# LPC5411x register map
Vendor: nxp.com; File version: 1.2
CPU: CM4 r0p1, little endian, MPU, FPU, VTOR, vendor SysTick, 3 interrupt priority bits
Registers are 32-bit, read-write, reset 0x0 unless marked. A register's access mark holds for its fields unless they carry their own. Offsets are from the block's base; [hi:lo] are bit positions; 'fields as' and 'values as' point back to an identical list.

## DMIC — LPC5411x Windowed Watchdog Timer (WWDT)
Base 0x40090000
0x00 OSR0 — Oversample Rate register 0
  [7:0] OSR — Selects the oversample rate for the related input channel.
0x04 DIVHFCLK0 — DMIC Clock Register 0
  [3:0] PDMDIV — PDM clock divider value. 0 = divide by 1 1 = divide by 2 2 = divide by 3 3 = divide by 4 4 = divide by 6 5 = divide by 8 6 = divide by 12 7 = divide by 16 8 = divide by 24 9 = divide by 32 10 = divide by 48 11 = divide by 64 12 = divide by 96 13 = divide by 128 others = reserved.
0x08 PREAC2FSCOEF0 — Pre-Emphasis Filter Coefficient for 2 FS register
  [1:0] COMP — Pre-emphasis filer coefficient for 2 FS mode. 0 = Compensation = 0 1 = Compensation = 16 2 = Compensation = 15 3 = Compensation = 13
0x0C PREAC4FSCOEF0 — Pre-Emphasis Filter Coefficient for 4 FS register
  [1:0] COMP — Pre-emphasis filer coefficient for 4 FS mode. 0 = Compensation = 0 1 = Compensation = 16 2 = Compensation = 15 3 = Compensation = 13
0x10 GAINSHIFT0 — Decimator Gain Shift register
  [5:0] GAIN — Gain control, as a positive or negative (two's complement) number of bits to shift.
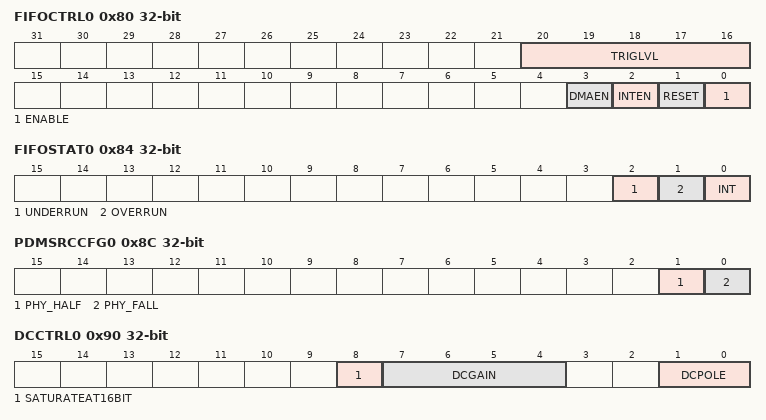
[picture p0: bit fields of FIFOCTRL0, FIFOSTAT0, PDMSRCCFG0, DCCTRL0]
0x80 FIFOCTRL0 — FIFO Control register 0
  [20:16] TRIGLVL — FIFO trigger level. Selects the data trigger level for interrupt or DMA operation. If enabled to do so, the FIFO level can wake up the device just enough to perform DMA, then return to the reduced power mode See Section 4.5.66 'Hardware Wake-up control register'. 0 = trigger when the FIFO has received one entry (is no longer empty). 1 = trigger when the FIFO has received two entries. 15 = trigger when the FIFO has received 16 entries (has become full).
  [3] DMAEN — DMA enable
    0=DISABLED (DMA requests are not enabled.); 1=ENABLED (DMA requests based on FIFO level are enabled.)
  [2] INTEN — Interrupt enable.
    0=DISABLED (FIFO level interrupts are not enabled.); 1=ENABLED (FIFO level interrupts are enabled.)
  [1] RESET — FIFO reset.
    0=NORMAL (Normal operation); 1=RESET (Reset the FIFO. This bit must be cleared before resuming operation)
  [0] ENABLE — FIFO enable.
    0=DISABLED (FIFO is not enabled. Enabling a DMIC channel with the FIFO disabled could be useful while data is being streamed to the I2S, or in order to avoid a filter settling delay when a channel is re-enabled after a period when the data was not needed.); 1=ENABLED (FIFO is enabled. The FIFO must be enabled in order for the CPU or DMA to read data from the DMIC via the FIFODATA register.)
0x84 FIFOSTAT0 — FIFO Status register 0
  [2] UNDERRUN — Underrun flag. Indicates that a FIFO underflow has occurred at some point. Writing a one to this bit clears the flag.
  [1] OVERRUN — Overrun flag. Indicates that a FIFO overflow has occurred at some point. Writing a one to this bit clears the flag. This flag does not cause an interrupt.
  [0] INT — Interrupt flag. Asserted when FIFO data reaches the level specified in the FIFOCTRL register. Writing a one to this bit clears the flag. Remark: note that the bus clock to the DMIC subsystem must be running in order for an interrupt to occur.
0x88 FIFODATA0 — FIFO Data Register 0
  [23:0] DATA — Data from the top of the input filter FIFO.
0x8C PDMSRCCFG0 — PDM Source Configuration register 0
  [1] PHY_HALF — Half rate sampling
    0=STANDARD (Standard half rate sampling. The clock to the DMIC is sent at the same rate as the decimator is providing.); 1=HALF_RATE (Use half rate sampling. The clock to the DMIC is sent at half the rate as the decimator is providing.)
  [0] PHY_FALL — Capture PDM_DATA
    0=RISING_EDGE (Capture PDM_DATA on the rising edge of PDM_CLK.); 1=FALLING_EDGE (Capture PDM_DATA on the falling edge of PDM_CLK.)
0x90 DCCTRL0 — DC Control register 0
  [8] SATURATEAT16BIT — Selects 16-bit saturation.
    0=DO_NOT_SATURATE (Results roll over if out range and do not saturate.); 1=SATURATE (If the result overflows, it saturates at 0xFFFF for positive overflow and 0x8000 for negative overflow.)
  [7:4] DCGAIN — Fine gain adjustment in the form of a number of bits to downshift.
  [1:0] DCPOLE — DC block filter
    0=FLAT_RESPONSE (Flat response, no filter.); 1=155_HZ; 2=78_HZ; 3=39_HZ
0x100 OSR1 — Oversample Rate register 1
  fields as OSR0
0x104 DIVHFCLK1 — DMIC Clock Register 1
  fields as DIVHFCLK0
0x108 PREAC2FSCOEF1 — Pre-Emphasis Filter Coefficient for 2 FS register
  fields as PREAC2FSCOEF0
0x10C PREAC4FSCOEF1 — Pre-Emphasis Filter Coefficient for 4 FS register
  fields as PREAC4FSCOEF0
0x110 GAINSHIFT1 — Decimator Gain Shift register
  fields as GAINSHIFT0
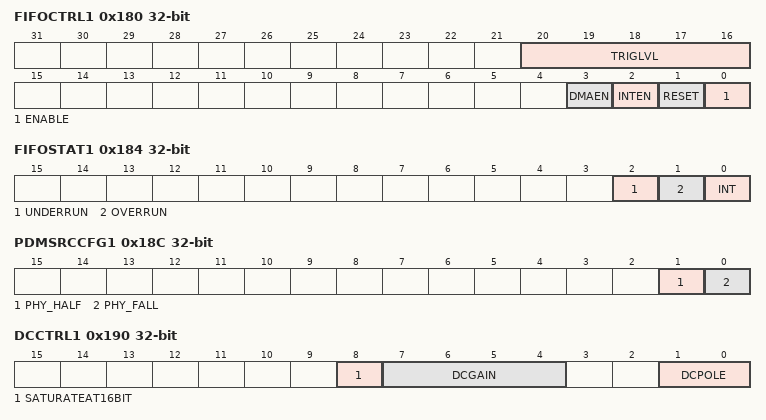
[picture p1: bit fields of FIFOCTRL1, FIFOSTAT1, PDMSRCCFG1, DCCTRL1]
0x180 FIFOCTRL1 — FIFO Control register 1
  fields as FIFOCTRL0
0x184 FIFOSTAT1 — FIFO Status register 1
  fields as FIFOSTAT0
0x188 FIFODATA1 — FIFO Data Register 1
  [23:0] DATA — Data from the top of the input filter FIFO.
0x18C PDMSRCCFG1 — PDM Source Configuration register 1
  fields as PDMSRCCFG0
0x190 DCCTRL1 — DC Control register 1
  fields as DCCTRL0
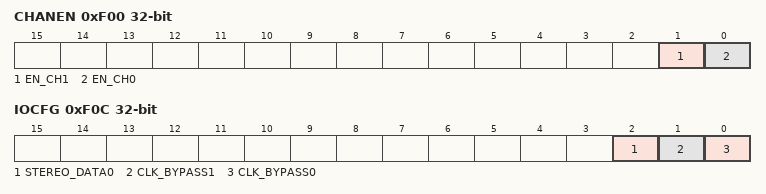
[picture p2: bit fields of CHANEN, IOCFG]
0xF00 CHANEN — Channel Enable register
  [1] EN_CH1 — Enable channel 1. When 1, PDM channel 1 is enabled.
  [0] EN_CH0 — Enable channel 0. When 1, PDM channel 0 is enabled.
0xF0C IOCFG — I/O Configuration register
  [2] STEREO_DATA0 — Stereo PDM select. When 1, PDM_DATA0 is routed to both PDM channels in a configuration that supports a single stereo digital microphone.
  [1] CLK_BYPASS1 — Bypass CLK1. When 1, PDM_DATA1 becomes the clock for PDM channel 1. This provides for the possibility of an external codec taking over the PDM bus.
  [0] CLK_BYPASS0 — Bypass CLK0. When 1, PDM_DATA1 becomes the clock for PDM channel 0. This provides for the possibility of an external codec taking over the PDM bus.
0xF10 USE2FS
  [0] USE2FS
    0=1FS (Use 1FS output for PCM data.); 1=2FS (Use 2FS output for PCM data.)
0xF80 HWVADGAIN reset 0x5 — HWVAD input gain register
  [3:0] INPUTGAIN — Shift value for input bits 0x00 -10 bits 0x01 -8 bits 0x02 -6 bits 0x03 -4 bits 0x04 -2 bits 0x05 0 bits (default) 0x06 +2 bits 0x07 +4 bits 0x08 +6 bits 0x09 +8 bits 0x0A +10 bits 0x0B +12 bits 0x0C +14 bits 0x0D to 0x0F Reserved.
0xF84 HWVADHPFS reset 0x1 — HWVAD filter control register
  [1:0] HPFS — High pass filter
    0=BYPASS (First filter by-pass.); 1=HIGH_PASS_1750HZ (High pass filter with -3dB cut-off at 1750Hz.); 2=HIGH_PASS_215HZ (High pass filter with -3dB cut-off at 215Hz.)
0xF88 HWVADST10 — HWVAD control register
  [0] ST10 — Stage 0
    0=NORMAL (Normal operation, waiting for HWVAD trigger event (stage 0).); 1=RESET (Reset internal interrupt flag by writing a '1' pulse.)
0xF8C HWVADRSTT — HWVAD filter reset register
  [0] RSTT — Writing a 1 resets all filter values
0xF90 HWVADTHGN — HWVAD noise estimator gain register
  [3:0] THGN — Gain value for the noise estimator. Values 0 to 14. 0 corresponds to a gain of 1.
0xF94 HWVADTHGS reset 0x4 — HWVAD signal estimator gain register
  [3:0] THGS — Gain value for the signal estimator. Values 0 to 14. 0 corresponds to a gain of 1.
0xF98 HWVADLOWZ — HWVAD noise envelope estimator register
  [15:0] LOWZ ro — Noise envelope estimator value.
0xFFC ID reset 0x2 — Module Identification register
  [31:0] ID ro — Indicates module ID and the number of channels in this DMIC interface.
